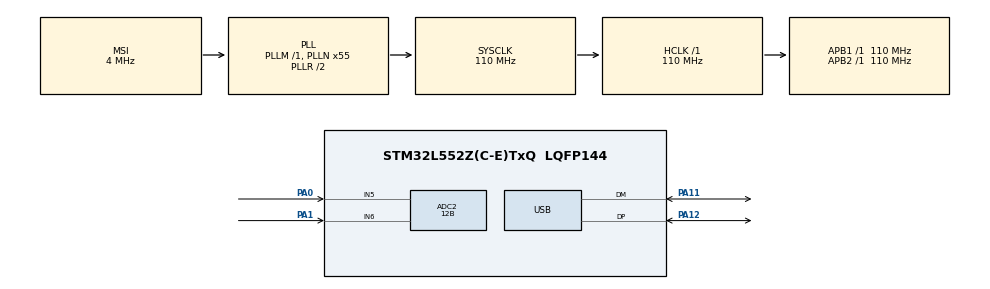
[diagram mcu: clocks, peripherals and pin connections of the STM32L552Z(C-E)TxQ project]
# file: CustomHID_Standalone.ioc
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ADC2.AWD1HighThreshold=0
ADC2.AWD1ITMode=DISABLE
ADC2.AWD1LowThreshold=0
ADC2.Channel-2\#ChannelRegularConversion=ADC_CHANNEL_5
ADC2.Channel-IN5=ADC_CHANNEL_5
ADC2.ClockPrescaler=ADC_CLOCK_SYNC_PCLK_DIV2
ADC2.ContinuousConvMode=DISABLE
ADC2.DMAContinuousRequests=ENABLE
ADC2.DataAlign=ADC_DATAALIGN_RIGHT
ADC2.DiscontinuousConvMode=DISABLE
ADC2.EOCSelection=ADC_EOC_SINGLE_CONV
ADC2.EnableAnalogWatchDog1=true
ADC2.EnableAnalogWatchDog2=false
ADC2.EnableAnalogWatchDog3=false
ADC2.EnableInjectedConversion=DISABLE
ADC2.EnableRegularConversion=ENABLE
ADC2.ExternalTrigConv=ADC_EXTERNALTRIG_T1_TRGO
ADC2.ExternalTrigConvEdge=ADC_EXTERNALTRIGCONVEDGE_RISING
ADC2.LowPowerAutoWait=DISABLE
ADC2.Mode=ADC_MODE_INDEPENDENT
ADC2.NbrOfConversion=1
ADC2.OffsetNumber-2\#ChannelRegularConversion=ADC_OFFSET_NONE
ADC2.Overrun=ADC_OVR_DATA_PRESERVED
ADC2.OversamplingMode=DISABLE
ADC2.Rank-2\#ChannelRegularConversion=1
ADC2.Resolution=ADC_RESOLUTION_12B
ADC2.SamplingTime-2\#ChannelRegularConversion=ADC_SAMPLETIME_2CYCLES_5
ADC2.ScanConvMode=ADC_SCAN_DISABLE
ADC2.SingleDiff-2\#ChannelRegularConversion=ADC_DIFFERENTIAL_ENDED
ADC2.WatchdogChannel=ADC_CHANNEL_5
ADC2.WatchdogMode=ADC_ANALOGWATCHDOG_SINGLE_REG
Dma.ADC2.0.Channel_PRIV_NPRIV=DMA_CHANNEL_NPRIV_DISABLE
Dma.ADC2.0.Direction=DMA_PERIPH_TO_MEMORY
Dma.ADC2.0.EventEnable=DISABLE
Dma.ADC2.0.Instance=DMA1_Channel1
Dma.ADC2.0.MemDataAlignment=DMA_MDATAALIGN_BYTE
Dma.ADC2.0.MemInc=DMA_MINC_DISABLE
Dma.ADC2.0.Mode=DMA_CIRCULAR
Dma.ADC2.0.PeriphDataAlignment=DMA_PDATAALIGN_BYTE
Dma.ADC2.0.PeriphInc=DMA_PINC_DISABLE
Dma.ADC2.0.Polarity=HAL_DMAMUX_REQ_GEN_RISING
Dma.ADC2.0.Priority=DMA_PRIORITY_LOW
Dma.ADC2.0.RequestNumber=1
Dma.ADC2.0.SignalID=NONE
Dma.ADC2.0.SyncEnable=ENABLE
Dma.ADC2.0.SyncPolarity=HAL_DMAMUX_SYNC_RISING
Dma.ADC2.0.SyncRequestNumber=1
Dma.ADC2.0.SyncSignalID=NONE
Dma.Request0=ADC2
Mcu.Family=STM32L5
Mcu.Name=STM32L552Z(C-E)TxQ
Mcu.Package=LQFP144
NVIC.DMA1_Channel1_IRQn=true\:3\:0\:false\:false\:true\:false\:true\:true
NVIC.DMAMUX1_IRQn=true\:0\:0\:false\:false\:true\:false\:true\:true
NVIC.PriorityGroup=NVIC_PRIORITYGROUP_3
NVIC.USB_FS_IRQn=true\:6\:0\:true\:false\:true\:true\:true\:true
PA0.Signal=ADCx_IN5
PA1.Signal=ADCx_IN6
PA11.Mode=Device
PA11.Signal=USB_DM
PA12.Mode=Device
PA12.Signal=USB_DP
ProjectManager.HeapSize=0x400
ProjectManager.StackSize=0x800
ProjectManager.TargetToolchain=EWARM V8.32
RCC.ADCCLockSelection=RCC_ADCCLKSOURCE_SYSCLK
RCC.ADCFreq_Value=110000000
RCC.AHBFreq_Value=110000000
RCC.APB1Freq_Value=110000000
RCC.APB1TimFreq_Value=110000000
RCC.APB2Freq_Value=110000000
RCC.APB2TimFreq_Value=110000000
RCC.CK48CLockSelection=RCC_USBCLKSOURCE_HSI48
RCC.CortexFreq_Value=110000000
RCC.DATA_CACHE_ENABLE=0
RCC.HCLKFreq_Value=110000000
RCC.HSE_VALUE=8000000
RCC.HSI48_VALUE=48000000
RCC.HSI_VALUE=16000000
RCC.INSTRUCTION_CACHE_ENABLE=0
RCC.LSE_VALUE=32768
RCC.MSI_VALUE=4000000
RCC.PLLN=55
RCC.SYSCLKFreq_VALUE=110000000
RCC.SYSCLKSource=RCC_SYSCLKSOURCE_PLLCLK
RCC.USBFreq_Value=48000000
RCC.VCOOutputFreq_Value=220000000
SH.ADCx_IN5.0=ADC2_IN5,IN5-Differential
SH.ADCx_IN6.0=ADC2_IN6,IN5-Differential
TIM1.AutoReloadPreload=TIM_AUTORELOAD_PRELOAD_DISABLE
TIM1.ClockDivision=TIM_CLOCKDIVISION_DIV1
TIM1.CounterMode=TIM_COUNTERMODE_UP
TIM1.Period=499
TIM1.Prescaler=149
TIM1.RepetitionCounter=0
TIM1.TIM_MasterOutputTrigger=TIM_TRGO_UPDATE
TIM1.TIM_MasterOutputTrigger2=TIM_TRGO2_RESET
TIM1.TIM_MasterSlaveMode=TIM_MASTERSLAVEMODE_DISABLE
USB.DeviceSpeed=PCD_SPEED_FULL
USB.Sof_enable=DISABLE
USB.battery_charging_enable=DISABLE
USB.low_power_enable=DISABLE
USB.lpm_enable=DISABLE
USB.phy_itface=PCD_PHY_EMBEDDED
USB_DEVICE.CLASS_NAME_FS=CUSTOM_HID
USB_DEVICE.CONFIGURATION_STRING_CUSTOMHID_FS=Custom HID Config
USB_DEVICE.CUSTOM_HID_FS_BINTERVAL=0x5
USB_DEVICE.INTERFACE_STRING_CUSTOMHID_FS=Custom HID Interface
USB_DEVICE.LANGID_STRING=1033
USB_DEVICE.MANUFACTURER_STRING=STMicroelectronics
USB_DEVICE.PID_CUSTOMHID_FS=0x5750
USB_DEVICE.PRODUCT_STRING_CUSTOMHID_FS=STM32 Custom Human interface
USB_DEVICE.USBD_CUSTOMHID_OUTREPORT_BUF_SIZE=2
USB_DEVICE.USBD_CUSTOM_HID_REPORT_DESC_SIZE=163
USB_DEVICE.USBD_DEBUG_LEVEL=0
USB_DEVICE.USBD_LPM_ENABLED=1
USB_DEVICE.USBD_MAX_NUM_CONFIGURATION=1
USB_DEVICE.USBD_MAX_NUM_INTERFACES=1
USB_DEVICE.USBD_MAX_STR_DESC_SIZ=64
USB_DEVICE.USBD_SELF_POWERED=1
USB_DEVICE.VID=0x483
USB_DEVICE.VirtualMode=CustomHid
USB_DEVICE.VirtualModeFS=Custom_Hid_FS
VP_ICACHE_VS_ICACHE.Mode=DirectMappedCache
VP_PWR_VS_DBSignals.Mode=DisableDeadBatterySignals
VP_PWR_VS_SECSignals.Mode=Security/Privilege
VP_RCC_USB.Mode=CRS SYNC Source USB
VP_TIM1_VS_ClockSourceINT.Mode=Internal
VP_USB_DEVICE_VS_USB_DEVICE_CUSTOM_HID_FS.Mode=CUSTOM_HID_FS
board=STM32L552E_EVAL

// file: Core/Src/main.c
/* USER CODE BEGIN Header */
/**
  ******************************************************************************
  * @file    USB_Device/CustomHID_Standalone/Core/Src/main.c
  * @author  MCD Application Team
  * @brief   USB device HID demo main file
  ******************************************************************************
  * @attention
  *
  * Copyright (c) 2019 STMicroelectronics.
  * All rights reserved.
  *
  * This software is licensed under terms that can be found in the LICENSE file
  * in the root directory of this software component.
  * If no LICENSE file comes with this software, it is provided AS-IS.
  *
  ******************************************************************************
  */
/* USER CODE END Header */
#include "main.h"
#include "usb_device.h"

ADC_HandleTypeDef hadc2;
DMA_HandleTypeDef hdma_adc2;

TIM_HandleTypeDef htim1;

void SystemClock_Config(void);
static void MX_GPIO_Init(void);
static void MX_DMA_Init(void);
static void MX_ICACHE_Init(void);
static void MX_ADC2_Init(void);
static void MX_TIM1_Init(void);

int main(void)
{

  /* MCU Configuration--------------------------------------------------------*/

  /* Reset of all peripherals, Initializes the Flash interface and the Systick. */
  HAL_Init();

  /* Configure the system clock */
  SystemClock_Config();

  /* Initialize all configured peripherals */
  MX_GPIO_Init();
  MX_DMA_Init();
  MX_ICACHE_Init();
  MX_USB_Device_Init();
  MX_ADC2_Init();
  MX_TIM1_Init();
  /* USER CODE BEGIN 2 */
  /* Configure the application hardware resources */
  BSP_LED_Init(LED5);
  /* USER CODE END 2 */

  /* Infinite loop */
  while (1)
  {

  }
}

void SystemClock_Config(void)
{
  RCC_OscInitTypeDef RCC_OscInitStruct = {0};
  RCC_ClkInitTypeDef RCC_ClkInitStruct = {0};
  RCC_CRSInitTypeDef RCC_CRSInitStruct = {0};

  /** Configure the main internal regulator output voltage
  */
  if (HAL_PWREx_ControlVoltageScaling(PWR_REGULATOR_VOLTAGE_SCALE0) != HAL_OK)
  {
    Error_Handler();
  }

  /** Initializes the RCC Oscillators according to the specified parameters
  * in the RCC_OscInitTypeDef structure.
  */
  RCC_OscInitStruct.OscillatorType = RCC_OSCILLATORTYPE_HSI48|RCC_OSCILLATORTYPE_MSI;
  RCC_OscInitStruct.HSI48State = RCC_HSI48_ON;
  RCC_OscInitStruct.MSIState = RCC_MSI_ON;
  RCC_OscInitStruct.MSICalibrationValue = RCC_MSICALIBRATION_DEFAULT;
  RCC_OscInitStruct.MSIClockRange = RCC_MSIRANGE_6;
  RCC_OscInitStruct.PLL.PLLState = RCC_PLL_ON;
  RCC_OscInitStruct.PLL.PLLSource = RCC_PLLSOURCE_MSI;
  RCC_OscInitStruct.PLL.PLLM = 1;
  RCC_OscInitStruct.PLL.PLLN = 55;
  RCC_OscInitStruct.PLL.PLLP = RCC_PLLP_DIV7;
  RCC_OscInitStruct.PLL.PLLQ = RCC_PLLQ_DIV2;
  RCC_OscInitStruct.PLL.PLLR = RCC_PLLR_DIV2;
  if (HAL_RCC_OscConfig(&RCC_OscInitStruct) != HAL_OK)
  {
    Error_Handler();
  }

  /** Initializes the CPU, AHB and APB buses clocks
  */
  RCC_ClkInitStruct.ClockType = RCC_CLOCKTYPE_HCLK|RCC_CLOCKTYPE_SYSCLK
                              |RCC_CLOCKTYPE_PCLK1|RCC_CLOCKTYPE_PCLK2;
  RCC_ClkInitStruct.SYSCLKSource = RCC_SYSCLKSOURCE_PLLCLK;
  RCC_ClkInitStruct.AHBCLKDivider = RCC_SYSCLK_DIV1;
  RCC_ClkInitStruct.APB1CLKDivider = RCC_HCLK_DIV1;
  RCC_ClkInitStruct.APB2CLKDivider = RCC_HCLK_DIV1;

  if (HAL_RCC_ClockConfig(&RCC_ClkInitStruct, FLASH_LATENCY_5) != HAL_OK)
  {
    Error_Handler();
  }

  /** Enable the SYSCFG APB clock
  */
  __HAL_RCC_CRS_CLK_ENABLE();

  /** Configures CRS
  */
  RCC_CRSInitStruct.Prescaler = RCC_CRS_SYNC_DIV1;
  RCC_CRSInitStruct.Source = RCC_CRS_SYNC_SOURCE_USB;
  RCC_CRSInitStruct.Polarity = RCC_CRS_SYNC_POLARITY_RISING;
  RCC_CRSInitStruct.ReloadValue = __HAL_RCC_CRS_RELOADVALUE_CALCULATE(48000000,1000);
  RCC_CRSInitStruct.ErrorLimitValue = 34;
  RCC_CRSInitStruct.HSI48CalibrationValue = 32;

  HAL_RCCEx_CRSConfig(&RCC_CRSInitStruct);
}

static void MX_ADC2_Init(void)
{

  ADC_AnalogWDGConfTypeDef AnalogWDGConfig = {0};
  ADC_ChannelConfTypeDef sConfig = {0};

  /** Common config
  */
  hadc2.Instance = ADC2;
  hadc2.Init.ClockPrescaler = ADC_CLOCK_SYNC_PCLK_DIV2;
  hadc2.Init.Resolution = ADC_RESOLUTION_12B;
  hadc2.Init.DataAlign = ADC_DATAALIGN_RIGHT;
  hadc2.Init.ScanConvMode = ADC_SCAN_DISABLE;
  hadc2.Init.EOCSelection = ADC_EOC_SINGLE_CONV;
  hadc2.Init.LowPowerAutoWait = DISABLE;
  hadc2.Init.ContinuousConvMode = DISABLE;
  hadc2.Init.NbrOfConversion = 1;
  hadc2.Init.DiscontinuousConvMode = DISABLE;
  hadc2.Init.ExternalTrigConv = ADC_EXTERNALTRIG_T1_TRGO;
  hadc2.Init.ExternalTrigConvEdge = ADC_EXTERNALTRIGCONVEDGE_RISING;
  hadc2.Init.DMAContinuousRequests = ENABLE;
  hadc2.Init.Overrun = ADC_OVR_DATA_PRESERVED;
  hadc2.Init.OversamplingMode = DISABLE;
  if (HAL_ADC_Init(&hadc2) != HAL_OK)
  {
    Error_Handler();
  }

  /** Configure Analog WatchDog 1
  */
  AnalogWDGConfig.WatchdogNumber = ADC_ANALOGWATCHDOG_1;
  AnalogWDGConfig.WatchdogMode = ADC_ANALOGWATCHDOG_SINGLE_REG;
  AnalogWDGConfig.Channel = ADC_CHANNEL_5;
  AnalogWDGConfig.ITMode = DISABLE;
  AnalogWDGConfig.HighThreshold = 0;
  AnalogWDGConfig.LowThreshold = 0;
  if (HAL_ADC_AnalogWDGConfig(&hadc2, &AnalogWDGConfig) != HAL_OK)
  {
    Error_Handler();
  }

  /** Configure Regular Channel
  */
  sConfig.Channel = ADC_CHANNEL_5;
  sConfig.Rank = ADC_REGULAR_RANK_1;
  sConfig.SamplingTime = ADC_SAMPLETIME_2CYCLES_5;
  sConfig.SingleDiff = ADC_DIFFERENTIAL_ENDED;
  sConfig.OffsetNumber = ADC_OFFSET_NONE;
  sConfig.Offset = 0;
  if (HAL_ADC_ConfigChannel(&hadc2, &sConfig) != HAL_OK)
  {
    Error_Handler();
  }

}

static void MX_ICACHE_Init(void)
{

  /** Enable instruction cache in 1-way (direct mapped cache)
  */
  if (HAL_ICACHE_ConfigAssociativityMode(ICACHE_1WAY) != HAL_OK)
  {
    Error_Handler();
  }
  if (HAL_ICACHE_Enable() != HAL_OK)
  {
    Error_Handler();
  }

}

static void MX_TIM1_Init(void)
{

  TIM_ClockConfigTypeDef sClockSourceConfig = {0};
  TIM_MasterConfigTypeDef sMasterConfig = {0};

  htim1.Instance = TIM1;
  htim1.Init.Prescaler = 149;
  htim1.Init.CounterMode = TIM_COUNTERMODE_UP;
  htim1.Init.Period = 499;
  htim1.Init.ClockDivision = TIM_CLOCKDIVISION_DIV1;
  htim1.Init.RepetitionCounter = 0;
  htim1.Init.AutoReloadPreload = TIM_AUTORELOAD_PRELOAD_DISABLE;
  if (HAL_TIM_Base_Init(&htim1) != HAL_OK)
  {
    Error_Handler();
  }
  sClockSourceConfig.ClockSource = TIM_CLOCKSOURCE_INTERNAL;
  if (HAL_TIM_ConfigClockSource(&htim1, &sClockSourceConfig) != HAL_OK)
  {
    Error_Handler();
  }
  sMasterConfig.MasterOutputTrigger = TIM_TRGO_UPDATE;
  sMasterConfig.MasterOutputTrigger2 = TIM_TRGO2_RESET;
  sMasterConfig.MasterSlaveMode = TIM_MASTERSLAVEMODE_DISABLE;
  if (HAL_TIMEx_MasterConfigSynchronization(&htim1, &sMasterConfig) != HAL_OK)
  {
    Error_Handler();
  }

}

static void MX_DMA_Init(void)
{

  /* DMA controller clock enable */
  __HAL_RCC_DMAMUX1_CLK_ENABLE();
  __HAL_RCC_DMA1_CLK_ENABLE();

  /* DMA interrupt init */
  /* DMAMUX1_IRQn interrupt configuration */
  HAL_NVIC_SetPriority(DMAMUX1_IRQn, 0, 0);
  HAL_NVIC_EnableIRQ(DMAMUX1_IRQn);
  /* DMA1_Channel1_IRQn interrupt configuration */
  HAL_NVIC_SetPriority(DMA1_Channel1_IRQn, 3, 0);
  HAL_NVIC_EnableIRQ(DMA1_Channel1_IRQn);

}

static void MX_GPIO_Init(void)
{

  /* GPIO Ports Clock Enable */
  __HAL_RCC_GPIOA_CLK_ENABLE();

}

/* USER CODE BEGIN 4 */
/**
  * @brief This function provides accurate delay (in milliseconds) based
  * on SysTick counter flag.
  * @note This function is declared as __weak to be overwritten in case of other
  * implementations in user file.
  * @param Delay: specifies the delay time length, in milliseconds.
  * @retval None
  */
void HAL_Delay(__IO uint32_t Delay)
{
  while (Delay)
  {
    if (SysTick->CTRL & SysTick_CTRL_COUNTFLAG_Msk)
    {
      Delay--;
    }
  }
}
/* USER CODE END 4 */

void Error_Handler(void)
{
  /* USER CODE BEGIN Error_Handler_Debug */
  BSP_LED_On(LED5);
  while (1)
  {
  }
  /* USER CODE END Error_Handler_Debug */
}
